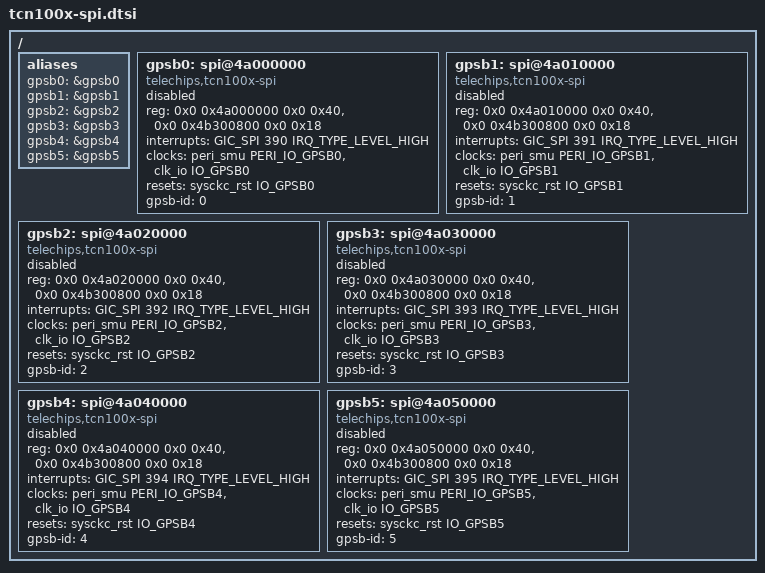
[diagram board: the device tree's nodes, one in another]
// SPDX-License-Identifier: (GPL-2.0-or-later OR MIT)
/*
 * Copyright (C) 2023 Telechips Inc.
 */

#include <dt-bindings/clock/telechips,tcn100x-clks.h>
#include <dt-bindings/interrupt-controller/arm-gic.h>

/ {
	aliases: aliases {
		 gpsb0 = &gpsb0;
		 gpsb1 = &gpsb1;
		 gpsb2 = &gpsb2;
		 gpsb3 = &gpsb3;
		 gpsb4 = &gpsb4;
		 gpsb5 = &gpsb5;
	 };

	gpsb0: spi@4a000000 {
		compatible = "telechips,tcn100x-spi";
		reg = <0x0 0x4a000000 0x0 0x40>, /* base address */
		      <0x0 0x4b300800 0x0 0x18>; /* configuration */
		interrupts = <GIC_SPI 390 IRQ_TYPE_LEVEL_HIGH>;
		clocks = <&peri_smu PERI_IO_GPSB0 &clk_io IO_GPSB0>;
		resets = <&sysckc_rst IO_GPSB0>;
		reset-names = "iobus-gpsb0";
		gpsb-id = <0>;
		status = "disabled";
	};

	gpsb1: spi@4a010000 {
		compatible = "telechips,tcn100x-spi";
		reg = <0x0 0x4a010000 0x0 0x40>, /* base address */
		      <0x0 0x4b300800 0x0 0x18>; /* configuration */
		interrupts = <GIC_SPI 391 IRQ_TYPE_LEVEL_HIGH>;
		clocks = <&peri_smu PERI_IO_GPSB1 &clk_io IO_GPSB1>;
		resets = <&sysckc_rst IO_GPSB1>;
		reset-names = "iobus-gpsb1";
		gpsb-id = <1>;
		status = "disabled";
	};

	gpsb2: spi@4a020000 {
		compatible = "telechips,tcn100x-spi";
		reg = <0x0 0x4a020000 0x0 0x40>, /* base address */
		      <0x0 0x4b300800 0x0 0x18>; /* configuration */
		interrupts = <GIC_SPI 392 IRQ_TYPE_LEVEL_HIGH>;
		clocks = <&peri_smu PERI_IO_GPSB2 &clk_io IO_GPSB2>;
		resets = <&sysckc_rst IO_GPSB2>;
		reset-names = "iobus-gpsb2";
		gpsb-id = <2>;
		status = "disabled";
	};

	gpsb3: spi@4a030000 {
		compatible = "telechips,tcn100x-spi";
		reg = <0x0 0x4a030000 0x0 0x40>, /* base address */
		      <0x0 0x4b300800 0x0 0x18>; /* configuration */
		interrupts = <GIC_SPI 393 IRQ_TYPE_LEVEL_HIGH>;
		clocks = <&peri_smu PERI_IO_GPSB3 &clk_io IO_GPSB3>;
		resets = <&sysckc_rst IO_GPSB3>;
		reset-names = "iobus-gpsb3";
		gpsb-id = <3>;
		status = "disabled";
	};

	gpsb4: spi@4a040000 {
		compatible = "telechips,tcn100x-spi";
		reg = <0x0 0x4a040000 0x0 0x40>, /* base address */
		      <0x0 0x4b300800 0x0 0x18>; /* configuration */
		interrupts = <GIC_SPI 394 IRQ_TYPE_LEVEL_HIGH>;
		clocks = <&peri_smu PERI_IO_GPSB4 &clk_io IO_GPSB4>;
		resets = <&sysckc_rst IO_GPSB4>;
		reset-names = "iobus-gpsb4";
		gpsb-id = <4>;
		status = "disabled";
	};

	gpsb5: spi@4a050000 {
		compatible = "telechips,tcn100x-spi";
		reg = <0x0 0x4a050000 0x0 0x40>, /* base address */
		      <0x0 0x4b300800 0x0 0x18>; /* configuration */
		interrupts = <GIC_SPI 395 IRQ_TYPE_LEVEL_HIGH>;
		clocks = <&peri_smu PERI_IO_GPSB5 &clk_io IO_GPSB5>;
		resets = <&sysckc_rst IO_GPSB5>;
		reset-names = "iobus-gpsb5";
		gpsb-id = <5>;
		status = "disabled";
	};
};
